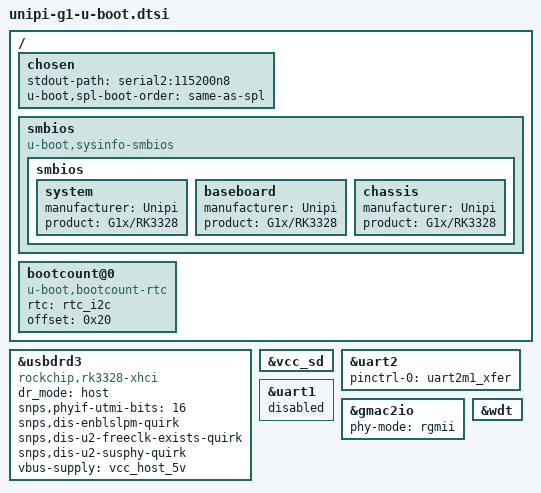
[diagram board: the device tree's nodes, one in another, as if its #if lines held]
// SPDX-License-Identifier: GPL-2.0+
/*
 * (C) Copyright 2016-2019 Rockchip Electronics Co., Ltd
 * (C) Copyright 2020 Radxa
 * (C) Copyright 2023 Unipi Technology s.r.o.
 */

#include "rk3328-u-boot.dtsi"
#include "rk3328-sdram-ddr3-666.dtsi"
#include "rk3328-sdram-ddr4-666a.dtsi"

/ {
	chosen {
		stdout-path = "serial2:115200n8";
		u-boot,spl-boot-order = "same-as-spl", &sdmmc, &emmc;
	};

	smbios {
		compatible = "u-boot,sysinfo-smbios";

		smbios {
			system {
				manufacturer = "Unipi";
				product = "G1x/RK3328";
			};

			baseboard {
				manufacturer = "Unipi";
				product = "G1x/RK3328";
			};

			chassis {
				manufacturer = "Unipi";
				product = "G1x/RK3328";
			};
		};
	};
#if IS_ENABLED(CONFIG_ID_EEPROM)
	bootcount@0 {
		compatible = "u-boot,bootcount-rtc";
		rtc = <&rtc_i2c>;
		offset = <0x20>;
	};
#endif
};


/*
 * Bind the Rockchip vendor xHCI glue (drivers/usb/host/xhci-rockchip.c)
 * instead of the generic dwc3 path. The vendor driver configures the UTMI
 * (USB2) PHY by hand and never enables the USB3OTG clocks, which avoids
 * disturbing the bugged InnoSilicon SuperSpeed PHY on RK3328. Override the
 * compatible so xhci-dwc3 (which matches "snps,dwc3") no longer binds here.
 */
&usbdrd3 {
	compatible = "rockchip,rk3328-xhci";
	dr_mode = "host";
	snps,phyif-utmi-bits = <16>;
	snps,dis-enblslpm-quirk;
	snps,dis-u2-freeclk-exists-quirk;
	snps,dis-u2-susphy-quirk;
	vbus-supply = <&vcc_host_5v>;
	status = "okay";
};

/* Need this and all the pinctrl/gpio stuff above to set pinmux */
&vcc_sd {
	bootph-pre-ram;
};

&uart2 {
	/delete-property/ rts-gpios;
	pinctrl-0 = <&uart2m1_xfer>;
	/delete-property/ linux,rs485-enabled-at-boot-time;
};

&uart1 {
	/delete-property/ rts-gpios;
	status = "disabled";
};

&gmac2io {
	phy-mode = "rgmii";
};

&wdt {
	status = "okay";
};
